# CONTROLSS_G3_EPWM29_CONTROLSS_G3_EPWM29 register map
Vendor: Texas Instruments
Registers are 16-bit, read-write, reset values left out (the file's numbers can be read two ways) unless marked. A register's access mark holds for its fields unless they carry their own. Offsets are as the file gives them; [hi:lo] are bit positions; {n}, {i} and the like mark numbered series.

## CONTROLSS_G3_EPWM29_CONTROLSS_G3_EPWM29 (part 3 of 4)
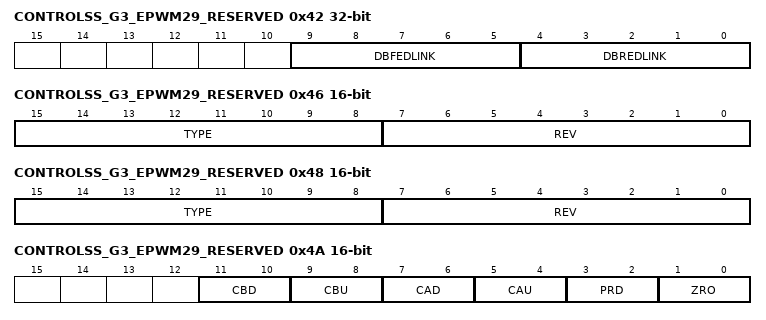
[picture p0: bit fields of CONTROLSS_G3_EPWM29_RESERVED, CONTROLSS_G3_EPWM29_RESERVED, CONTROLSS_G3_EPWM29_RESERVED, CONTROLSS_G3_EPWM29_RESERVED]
0x42 CONTROLSS_G3_EPWM29_RESERVED 32-bit
  [9:5] DBFEDLINK — DBFED_DBFEDHR Link Bits Writes to the DBFED:DBFEDHR registers in the ePWM module selected by the following bit selections results in a simultaneous write to the current ePWM module's DBFED_DBFEDHR registers. 00000: ePWM1 00001: ePWM2 00010: ePWM3 00011: ePWM4 00100: ePWM5 00101: ePWM6 00110: ePWM7 00111: ePWM8 01000: ePWM9 01001: ePWM10 01010: ePWM11 01011: ePWM12 01100: ePWM13 ... 11111: ePWM32
  [4:0] DBREDLINK — DBRED_DBREDHR Link Bits Writes to the DBRED:DBREDHR registers in the ePWM module selected by the following bit selections results in a simultaneous write to the current ePWM module's DBRED_DBREDHR registers. 00000: ePWM1 00001: ePWM2 00010: ePWM3 00011: ePWM4 00100: ePWM5 00101: ePWM6 00110: ePWM7 00111: ePWM8 01000: ePWM9 01001: ePWM10 01010: ePWM11 01011: ePWM12 01100: ePWM13 ... 11111: ePWM32
0x44 CONTROLSS_G3_EPWM29_RESERVED
  [0] CMPFIX_OVERRIDE — 0: Bug fix overriden 1: Bug fix takes effect
0x46 CONTROLSS_G3_EPWM29_RESERVED ro
  [15:8] TYPE — EPWM Type Bits: These bits specify the EPWM type. These bits are changed if the functionality of the EPWM is changed or any feature is added or removed:
  [7:0] REV — EPWM Silicon Revision Bits: These bits specify the EPWM revision. These bits are changed if any bug fixes are performed:
0x48 CONTROLSS_G3_EPWM29_RESERVED ro
  [15:8] TYPE — HRPWM Type Bits: These bits specify the HRPWM type. These bits are changed if the functionality of the HRPWM is changed or any feature is added or removed:
  [7:0] REV — HRPWM Silicon Revision Bits: These bits specify the HRPWM revision. These bits are changed if any bug fixes are performed:
0x4A CONTROLSS_G3_EPWM29_RESERVED
  [11:10] CBD — Action When TBCTR = CMPB on Down Count Note: By definition, in count up-down mode when the counter equals 0 the direction is defined as 1 or counting up. 00: Do nothing (action disabled) 01: Clear: force EPWMxA output low. 10: Set: force EPWMxA output high. 11: Toggle EPWMxA output: low output signal will be forced high, and a high signal will be forced low.
  [9:8] CBU — Action When TBCTR = CMPB on Up Count Note: By definition, in count up-down mode when the counter equals 0 the direction is defined as 1 or counting up. 00: Do nothing (action disabled) 01: Clear: force EPWMxA output low. 10: Set: force EPWMxA output high. 11: Toggle EPWMxA output: low output signal will be forced high, and a high signal will be forced low.
  [7:6] CAD — Action When TBCTR = CMPA on Down Count Note: By definition, in count up-down mode when the counter equals 0 the direction is defined as 1 or counting up. 00: Do nothing (action disabled) 01: Clear: force EPWMxA output low. 10: Set: force EPWMxA output high. 11: Toggle EPWMxA output: low output signal will be forced high, and a high signal will be forced low.
  [5:4] CAU — Action When TBCTR = CMPA on Up Count Note: By definition, in count up-down mode when the counter equals 0 the direction is defined as 1 or counting up. 00: Do nothing (action disabled) 01: Clear: force EPWMxA output low. 10: Set: force EPWMxA output high. 11: Toggle EPWMxA output: low output signal will be forced high, and a high signal will be forced low.
  [3:2] PRD — Action When TBCTR = TBPRD Note: By definition, in count up-down mode when the counter equals 0 the direction is defined as 1 or counting up. 00: Do nothing (action disabled) 01: Clear: force EPWMxA output low. 10: Set: force EPWMxA output high. 11: Toggle EPWMxA output: low output signal will be forced high, and a high signal will be forced low.
  [1:0] ZRO — Action When TBCTR = 0 Note: By definition, in count up-down mode when the counter equals 0 the direction is defined as 1 or counting up. 00: Do nothing (action disabled) 01: Clear: force EPWMxA output low. 10: Set: force EPWMxA output high. 11: Toggle EPWMxA output: low output signal will be forced high, and a high signal will be forced low.
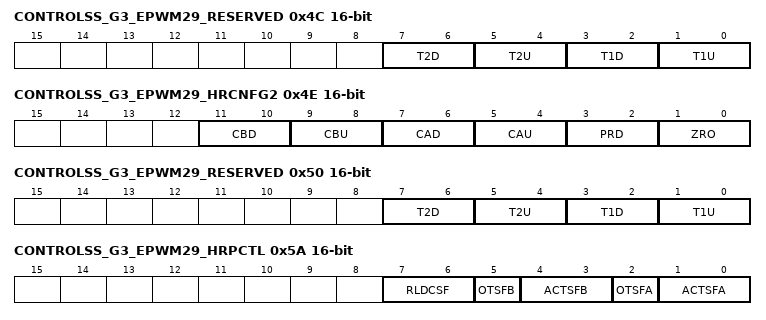
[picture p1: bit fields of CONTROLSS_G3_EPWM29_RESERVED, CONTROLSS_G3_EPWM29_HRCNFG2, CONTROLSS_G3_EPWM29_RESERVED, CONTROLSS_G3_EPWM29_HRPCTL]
0x4C CONTROLSS_G3_EPWM29_RESERVED
  [7:6] T2D — Action when event occurs on T2 in DOWN-Count Note: By definition, in count up-down mode when the counter equals 0 the direction is defined as 1 or counting up. 00: Do nothing (action disabled) 01: Clear: force EPWMxA output low. 10: Set: force EPWMxA output high. 11: Toggle EPWMxA output: low output signal will be forced high, and a high signal will be forced low.
  [5:4] T2U — Action when event occurs on T2 in UP-Count Note: By definition, in count up-down mode when the counter equals 0 the direction is defined as 1 or counting up. 00: Do nothing (action disabled) 01: Clear: force EPWMxA output low. 10: Set: force EPWMxA output high. 11: Toggle EPWMxA output: low output signal will be forced high, and a high signal will be forced low.
  [3:2] T1D — Action when event occurs on T1 in DOWN-Count Note: By definition, in count up-down mode when the counter equals 0 the direction is defined as 1 or counting up. 00: Do nothing (action disabled) 01: Clear: force EPWMxA output low. 10: Set: force EPWMxA output high. 11: Toggle EPWMxA output: low output signal will be forced high, and a high signal will be forced low.
  [1:0] T1U — Action when event occurs on T1 in UP-Count Note: By definition, in count up-down mode when the counter equals 0 the direction is defined as 1 or counting up. 00: Do nothing (action disabled) 01: Clear: force EPWMxA output low. 10: Set: force EPWMxA output high. 11: Toggle EPWMxA output: low output signal will be forced high, and a high signal will be forced low.
0x4E CONTROLSS_G3_EPWM29_HRCNFG2
  [11:10] CBD — Action When TBCTR = CMPB on Down Count Note: By definition, in count up-down mode when the counter equals 0 the direction is defined as 1 or counting up. 00: Do nothing (action disabled) 01: Clear: force EPWMxB output low. 10: Set: force EPWMxB output high. 11: Toggle EPWMxB output: low output signal will be forced high, and a high signal will be forced low.
  [9:8] CBU — Action When TBCTR = CMPB on Up Count Note: By definition, in count up-down mode when the counter equals 0 the direction is defined as 1 or counting up. 00: Do nothing (action disabled) 01: Clear: force EPWMxB output low. 10: Set: force EPWMxB output high. 11: Toggle EPWMxB output: low output signal will be forced high, and a high signal will be forced low.
  [7:6] CAD — Action When TBCTR = CMPA on Down Count Note: By definition, in count up-down mode when the counter equals 0 the direction is defined as 1 or counting up. 00: Do nothing (action disabled) 01: Clear: force EPWMxB output low. 10: Set: force EPWMxB output high. 11: Toggle EPWMxB output: low output signal will be forced high, and a high signal will be forced low.
  [5:4] CAU — Action When TBCTR = CMPA on Up Count Note: By definition, in count up-down mode when the counter equals 0 the direction is defined as 1 or counting up. 00: Do nothing (action disabled) 01: Clear: force EPWMxB output low. 10: Set: force EPWMxB output high. 11: Toggle EPWMxB output: low output signal will be forced high, and a high signal will be forced low.
  [3:2] PRD — Action When TBCTR = TBPRD Note: By definition, in count up-down mode when the counter equals 0 the direction is defined as 1 or counting up. 00: Do nothing (action disabled) 01: Clear: force EPWMxB output low. 10: Set: force EPWMxB output high. 11: Toggle EPWMxB output: low output signal will be forced high, and a high signal will be forced low.
  [1:0] ZRO — Action When TBCTR = 0 Note: By definition, in count up-down mode when the counter equals 0 the direction is defined as 1 or counting up. 00: Do nothing (action disabled) 01: Clear: force EPWMxB output low. 10: Set: force EPWMxB output high. 11: Toggle EPWMxB output: low output signal will be forced high, and a high signal will be forced low.
0x50 CONTROLSS_G3_EPWM29_RESERVED
  [7:6] T2D — Action when event occurs on T2 in DOWN-Count Note: By definition, in count up-down mode when the counter equals 0 the direction is defined as 1 or counting up. 00: Do nothing (action disabled) 01: Clear: force EPWMxB output low. 10: Set: force EPWMxB output high. 11: Toggle EPWMxB output: low output signal will be forced high, and a high signal will be forced low.
  [5:4] T2U — Action when event occurs on T2 in UP-Count Note: By definition, in count up-down mode when the counter equals 0 the direction is defined as 1 or counting up. 00: Do nothing (action disabled) 01: Clear: force EPWMxB output low. 10: Set: force EPWMxB output high. 11: Toggle EPWMxB output: low output signal will be forced high, and a high signal will be forced low.
  [3:2] T1D — Action when event occurs on T1 in DOWN-Count Note: By definition, in count up-down mode when the counter equals 0 the direction is defined as 1 or counting up. 00: Do nothing (action disabled) 01: Clear: force EPWMxB output low. 10: Set: force EPWMxB output high. 11: Toggle EPWMxB output: low output signal will be forced high, and a high signal will be forced low.
  [1:0] T1U — Action when event occurs on T1 in UP-Count Note: By definition, in count up-down mode when the counter equals 0 the direction is defined as 1 or counting up. 00: Do nothing (action disabled) 01: Clear: force EPWMxB output low. 10: Set: force EPWMxB output high. 11: Toggle EPWMxB output: low output signal will be forced high, and a high signal will be forced low.
0x5A CONTROLSS_G3_EPWM29_HRPCTL access not given
  [7:6] RLDCSF rw — AQCSFRC Active Register Reload From Shadow Options 00: Load on event counter equals zero 01: Load on event counter equals period 10: Load on event counter equals zero or counter equals period 11: Load immediately (the active register is directly accessed by the CPU and is not loaded from the shadow register).
  [5] OTSFB — One-Time Software Forced Event on Output B 0: Writing a 0 (zero) has no effect. Always reads back a 0. This bit is auto cleared once a write to this register is complete (i.e., a forced event is initiated.). This is a one-shot forced event. It can be overridden by another subsequent event on output B. 1: Initiates a single software forced event (access RW RRETURNS0S)
  [4:3] ACTSFB rw — Action When One-Time Software Force B is Invoked 00: Does nothing (action disabled) 01: Clear (low) 10: Set (high) 11: Toggle (Low -' High, High -' Low) Note: This action is not qualified by counter direction (CNT_dir)
  [2] OTSFA — One-Time Software Forced Event on Output A 0: Writing a 0 (zero) has no effect. Always reads back a 0. This bit is auto cleared once a write to this register is complete ( i.e., a forced event is initiated). This is a one-shot forced event. It can be overridden by another subsequent event on output A. 1: Initiates a single software forced event (access RW RRETURNS0S)
  [1:0] ACTSFA rw — Action When One-Time Software Force A Is Invoked 00: Does nothing (action disabled) 01: Clear (low) 10: Set (high) 11: Toggle (Low -' High, High -' Low) Note: This action is not qualified by counter direction (CNT_dir)
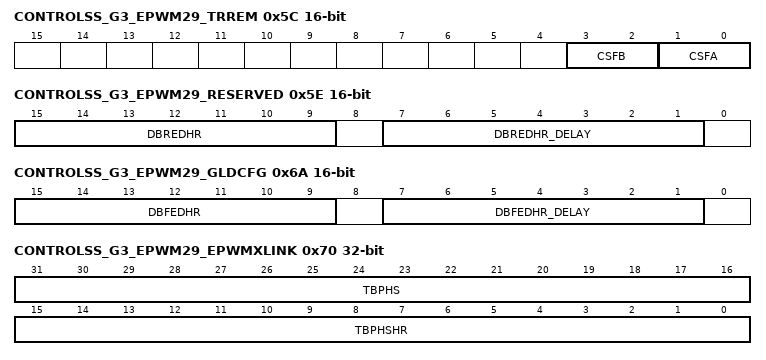
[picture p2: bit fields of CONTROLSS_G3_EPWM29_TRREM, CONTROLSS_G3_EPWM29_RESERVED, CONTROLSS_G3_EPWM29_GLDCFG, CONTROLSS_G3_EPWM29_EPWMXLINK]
0x5C CONTROLSS_G3_EPWM29_TRREM
  [3:2] CSFB — Continuous Software Force on Output B In immediate mode, a continuous force takes effect on the next TBCLK edge. In shadow mode, a continuous force takes effect on the next TBCLK edge after a shadow load into the active register. To configure shadow mode, use AQSFRC[RLDCSF]. 00: Software forcing is disabled and has no effect 01: Forces a continuous low on output B 10: Forces a continuous high on output B 11: Software forcing is disabled and has no effect
  [1:0] CSFA — Continuous Software Force on Output A In immediate mode, a continuous force takes effect on the next TBCLK edge. In shadow mode, a continuous force takes effect on the next TBCLK edge after a shadow load into the active register. 00: Software forcing is disabled and has no effect 01: Forces a continuous low on output A 10: Forces a continuous high on output A 11: Software forcing is disabled and has no effect
0x5E CONTROLSS_G3_EPWM29_RESERVED access per field
  [15:9] DBREDHR rw — Dead Band Rising Edge Delay High Resolution Bits
  [7:1] DBREDHR_DELAY ro — These 7-bits contain the results of OTTO calculation (if auto-conversion is enabled)
0x68 CONTROLSS_G3_EPWM29_GLDCTL
  [13:0] DBRED — Rising edge delay value
0x6A CONTROLSS_G3_EPWM29_GLDCFG access per field
  [15:9] DBFEDHR rw — Dead Band Falling Edge Delay High Resolution Bits
  [7:1] DBFEDHR_DELAY ro — These 7-bits contain the results of OTTO calculation (if auto-conversion is enabled)
0x6C CONTROLSS_G3_EPWM29_RESERVED
  [13:0] DBFED — Falling Edge Delay Count 14-bit counter
0x70 CONTROLSS_G3_EPWM29_EPWMXLINK 32-bit
  [31:16] TBPHS — Phase Offset Register These bits set time-base counter phase of the selected ePWM relative to the time-base that is supplying the synchronization input signal. - If TBCTL[PHSEN] = 0, then the synchronization event is ignored and the time-base counter is not loaded with the phase. - If TBCTL[PHSEN] = 1, then the time-base counter (TBCTR) will be loaded with the phase (TBPHS) when a synchronization event occurs. The synchronization event can be initiated by the input synchronization signal (EPWMxSYNCI) or by a software forced synchronization.
  [15:0] TBPHSHR — Phase Offset (High Resolution) Register. TBPHSHR must not be used. Instead TRREM (HRPWM remainder register) must be used to mimic the functionality of TBPHSHR. The lower 8 bits in this register are ignored - writes are ignored and reads return zero
0x74 CONTROLSS_G3_EPWM29_EPWMXLINK2
  [15:0] TBPRDHR — Period High Resolution Bits The upper 8-bits contain the high-resolution portion of the period value. The TBPRDHR register is not affected by the TBCTL[PRDLD] bit. Reads from this register always reflect the shadow register. Likewise writes are also to the shadow register. The TBPRDHR register is only used when the high resolution period feature is enabled. This register is only available with ePWM modules which support high-resolution period control. The lower 8 bits in this register are ignored - writes are ignored and reads return zero
0x78 CONTROLSS_G3_EPWM29_RESERVED
  [15:0] TBPRD — Time Base Period Register These bits determine the period of the time-base counter. This sets the PWM frequency. Shadowing of this register is enabled and disabled by the TBCTL[PRDLD] bit. By default this register is shadowed. - If TBCTL[PRDLD] = 0, then the shadow is enabled and any write or read will automatically go to the shadow register. In this case, the active register will be loaded from the shadow register when the time-base counter equals zero. - If TBCTL[PRDLD] = 1, then the shadow is disabled and any write or read will go directly to the active register, that is the register actively controlling the hardware. - The active and shadow registers share the same memory map address.
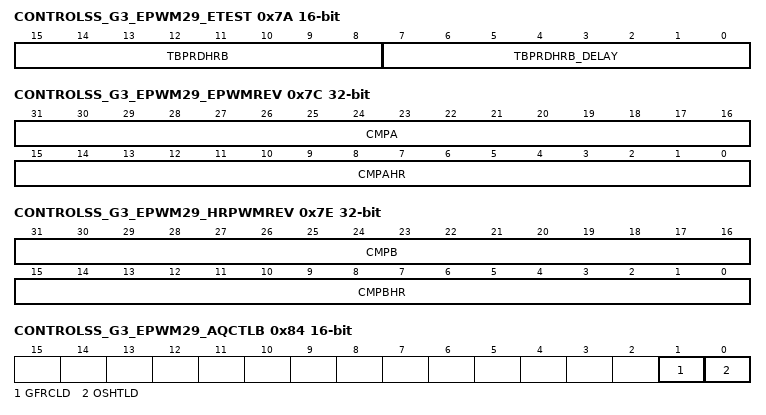
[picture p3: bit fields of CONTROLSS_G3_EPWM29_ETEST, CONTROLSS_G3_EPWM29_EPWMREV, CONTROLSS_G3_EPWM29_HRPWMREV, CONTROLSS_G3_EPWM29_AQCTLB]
0x7A CONTROLSS_G3_EPWM29_ETEST
  [15:8] TBPRDHRB — TBPRD High Resolution Calculation (2) Results for EPWMxB HRPWM Equations
  [7:0] TBPRDHRB_DELAY
0x7C CONTROLSS_G3_EPWM29_EPWMREV 32-bit
  [31:16] CMPA — Compare A Register The value in the active CMPA register is continuously compared to the time-base counter (TBCTR). When the values are equal, the counter-compare module generates a 'time-base counter equal to counter compare A' event. This event is sent to the action-qualifier where it is qualified and converted it into one or more actions. These actions can be applied to either the EPWMxA or the EPWMxB output depending on the configuration of the AQCTLA and AQCTLB registers. The actions that can be defined in the AQCTLA and AQCTLB registers include: - Do nothing the event is ignored. - Clear: Pull the EPWMxA and/or EPWMxB signal low - Set: Pull the EPWMxA and/or EPWMxB signal high - Toggle the EPWMxA and/or EPWMxB signal Shadowing of this register is enabled and disabled by the CMPCTL[SHDWAMODE] bit. By default this register is shadowed. - If CMPCTL[SHDWAMODE] = 0, then the shadow is enabled and anywrite or read will automatically go to the shadow register. In this case, the CMPCTL[LOADAMODE] bit field determines which event will load the active register from the shadow register. - Before a write, the CMPCTL[SHDWAFULL] bit can be read to determine if the shadow register is currently full. - If CMPCTL[SHDWAMODE] = 1, then the shadow register is disabled and any write or read will go directly to the active register, that is the register actively controlling the hardware. - In either mode, the active and shadow registers share the same memory map address.
  [15:0] CMPAHR — Compare A HRPWM Extension Register The UPPER 8-bits contain the high-resolution portion (most significant 8-bits) of the counter-compare A value. CMPA:CMPAHR can be accessed in a single 32-bit read/write. Shadowing is enabled and disabled by the CMPCTL[SHDWAMODE] bit as described for the CMPA register. The lower 8 bits in this register are ignored
0x7E CONTROLSS_G3_EPWM29_HRPWMREV 32-bit
  [31:16] CMPB — Compare B Register The value in the active CMPB register is continuously compared to the time-base counter (TBCTR). When the values are equal, the counter-compare module generates a 'time-base counter equal to counter compare B' event. This event is sent to the action-qualifier where it is qualified and converted it into one or more actions. These actions can be applied to either the EPWMxA or the EPWMxB output depending on the configuration of the AQCTLA and AQCTLB registers. The actions that can be defined in the AQCTLA and AQCTLB registers include: - Do nothing the event is ignored. - Clear: Pull the EPWMxA and/or EPWMxB signal low - Set: Pull the EPWMxA and/or EPWMxB signal high - Toggle the EPWMxA and/or EPWMxB signal Shadowing of this register is enabled and disabled by the CMPCTL[SHDWBMODE] bit. By default this register is shadowed. - If CMPCTL[SHDWBMODE] = 0, then the shadow is enabled and anywrite or read will automatically go to the shadow register. In this case, the CMPCTL[LOADBMODE] bit field determines which event will load the active register from the shadow register. - Before a write, the CMPCTL[SHDWBFULL] bit can be read to determine if the shadow register is currently full. - If CMPCTL[SHDWBMODE] = 1, then the shadow register is disabled and any write or read will go directly to the active register, that is the register actively controlling the hardware. - In either mode, the active and shadow registers share the same memory map address.
  [15:0] CMPBHR — Compare B High Resolution Bits The lower 8 bits in this register are ignored
0x80 CONTROLSS_G3_EPWM29_AQCTLA
  [15:0] CMPC — Compare C Register The value in the active CMPC register is continuously compared to the time-base counter (TBCTR). When the values are equal, the counter-compare module generates a 'time-base counter equal to counter compare C' event. Shadowing of this register is enabled and disabled by the CMPCTL2[SHDWCMODE] bit. By default this register is shadowed. - If CMPCTL2[SHDWCMODE] = 0, then the shadow is enabled and any write or read will automatically go to the shadow register. In this case, the CMPCTL2[LOADCMODE] bit field determines which event will load the active register from the shadow register: - If CMPCTL2[SHDWCMODE] = 1, then the shadow register is disabled and any write or read will go directly to the active register that is, the register actively controlling the hardware. - In either mode, the active and shadow registers share the same memory map address.
0x82 CONTROLSS_G3_EPWM29_AQCTLA2
  [15:0] CMPD — Compare D Register The value in the active CMPD register is continuously compared to the time-base counter (TBCTR). When the values are equal, the counter-compare module generates a 'time-base counter equal to counter compare D' event. Shadowing of this register is enabled and disabled by the CMPCTL2[SHDWDMODE] bit. By default this register is shadowed. - If CMPCTL2[SHDWDMODE] = 0, then the shadow is enabled and any write or read will automatically go to the shadow register. In this case, the CMPCTL2[LOADDMODE] bit field determines which event will load the active register from the shadow register: - If CMPCTL2[SHDWDMODE] = 1, then the shadow register is disabled and any write or read will go directly to the active register that is, the register actively controlling the hardware. - In either mode, the active and shadow registers share the same memory map address.
0x84 CONTROLSS_G3_EPWM29_AQCTLB access not given
  [1] GFRCLD — Force Load Event in One Shot Mode 0: Writing of 0 will be ignored. Always reads back a 0. 1: Force one load event at the input of the event pre-scale counter as shown in the diagram below. This bit is intended to be used for testing and/or software force loading of the events in global load mode. (access RW RRETURNS0S)
  [0] OSHTLD — Enable Reload Event in One Shot Mode 0: Writing of 0 will be ignored. Always reads back a 0. 1: Turns the one shot latch condition ON. Upon occurrence of a chosen load strobe, one shadow to active reload occurs and the latch will be cleared. Hence writing 1 to this bit would allow one load strobe event to pass through and block further strobe events. (access RW RRETURNS0S)
0x86 CONTROLSS_G3_EPWM29_AQCTLB2
  [15:0] SWVDELVAL — Software Valley Delay Value Register This register can be optionally used define offset value for the hardware calculated delay HWDELAYVAL as defined in VCAPCTL[VDELAYDIV] bits.
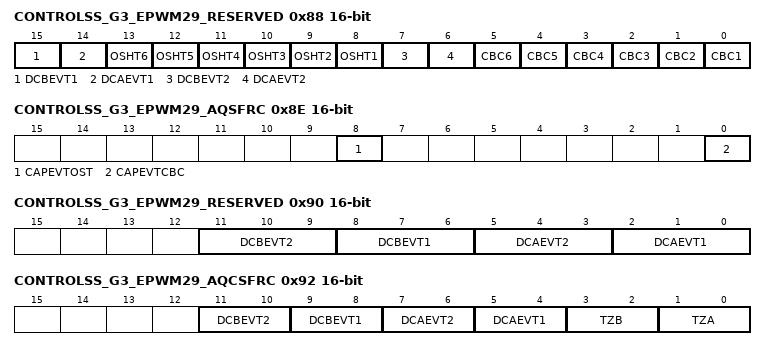
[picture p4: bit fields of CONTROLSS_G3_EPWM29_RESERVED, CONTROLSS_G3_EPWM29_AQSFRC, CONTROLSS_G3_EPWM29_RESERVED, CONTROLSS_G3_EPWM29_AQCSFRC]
0x88 CONTROLSS_G3_EPWM29_RESERVED
  [15] DCBEVT1 — Digital Compare Output B Event 1 Select 0: Disable DCBEVT1 as one-shot-trip source for this ePWM module. 1: Enable DCBEVT1 as one-shot-trip source for this ePWM module.
  [14] DCAEVT1 — Digital Compare Output A Event 1 Select 0: Disable DCAEVT1 as one-shot-trip source for this ePWM module. 1: Enable DCAEVT1 as one-shot-trip source for this ePWM module.
  [n+7] OSHT{n} (n=1..6) — Trip-zone {n} (TZ{n}) Select 0: Disable TZ{n} as a one-shot trip source for this ePWM module 1: Enable TZ{n} as a one-shot trip source for this ePWM module
  [7] DCBEVT2 — Digital Compare Output B Event 2 Select 0: Disable DCBEVT2 as a CBC trip source for this ePWM module 1: Enable DCBEVT2 as a CBC trip source for this ePWM module
  [6] DCAEVT2 — Digital Compare Output A Event 2 Select 0: Disable DCAEVT2 as a CBC trip source for this ePWM module 1: Enable DCAEVT2 as a CBC trip source for this ePWM module
  [n-1] CBC{n} (n=1..6) — Trip-zone {n} (TZ{n}) Select 0: Disable TZ{n} as a CBC trip source for this ePWM module 1: Enable TZ{n} as a CBC trip source for this ePWM module
0x8E CONTROLSS_G3_EPWM29_AQSFRC
  [8] CAPEVTOST — CAPEVT OST Select 0: Disable CAPEVT as a one-shot trip source for this ePWM module 1: Enable CAPEVT as a one-shot trip source for this ePWM module
  [0] CAPEVTCBC — CAPEVT CBC mode Select 0: Disable CAPEVT as a CBC trip source for this ePWM module 1: Enable CAPEVT as a CBC trip source for this ePWM module
0x90 CONTROLSS_G3_EPWM29_RESERVED
  [11:9] DCBEVT2 — Digital Compare Output B Event 2 Selection 000: Event disabled 001: DCBH = low, DCBL = don't care 010: DCBH = high, DCBL = don't care 011: DCBL = low, DCBH = don't care 100: DCBL = high, DCBH = don't care 101: DCBL = high, DCBH = low 110: Reserved 111: Reserved
  [8:6] DCBEVT1 — Digital Compare Output B Event 1 Selection 000: Event disabled 001: DCBH = low, DCBL = don't care 010: DCBH = high, DCBL = don't care 011: DCBL = low, DCBH = don't care 100: DCBL = high, DCBH = don't care 101: DCBL = high, DCBH = low 110: Reserved 111: Reserved
  [5:3] DCAEVT2 — Digital Compare Output A Event 2 Selection 000: Event disabled 001: DCAH = low, DCAL = don't care 010: DCAH = high, DCAL = don't care 011: DCAL = low, DCAH = don't care 100: DCAL = high, DCAH = don't care 101: DCAL = high, DCAH = low 110: Reserved 111: Reserved
  [2:0] DCAEVT1 — Digital Compare Output A Event 1 Selection 000: Event disabled 001: DCAH = low, DCAL = don't care 010: DCAH = high, DCAL = don't care 011: DCAL = low, DCAH = don't care 100: DCAL = high, DCAH = don't care 101: DCAL = high, DCAH = low 110: Reserved 111: Reserved
0x92 CONTROLSS_G3_EPWM29_AQCSFRC
  [11:10] DCBEVT2 — Digital Compare Output B Event 2 Action On EPWMxB 00: High-impedance (EPWMxB = High-impedance state) 01: Force EPWMxB to a high state. 10: Force EPWMxB to a low state. 11: Do Nothing, trip action is disabled
  [9:8] DCBEVT1 — Digital Compare Output B Event 1 Action On EPWMxB 00: High-impedance (EPWMxB = High-impedance state) 01: Force EPWMxB to a high state. 10: Force EPWMxB to a low state. 11: Do Nothing, trip action is disabled
  [7:6] DCAEVT2 — Digital Compare Output A Event 2 Action On EPWMxA 00: High-impedance (EPWMxA = High-impedance state) 01: Force EPWMxA to a high state. 10: Force EPWMxA to a low state. 11: Do Nothing, trip action is disabled
  [5:4] DCAEVT1 — Digital Compare Output A Event 1 Action On EPWMxA 00: High-impedance (EPWMxA = High-impedance state) 01: Force EPWMxA to a high state. 10: Force EPWMxA to a low state. 11: Do Nothing, trip action is disabled
  [3:2] TZB — TZ1 to TZ6, DCAEVT1/2, DCBEVT1/2Trip Action On EPWMxB When a trip event occurs the following action is taken on output EPWMxB. Which trip-zone pins can cause an event is defined in the TZSEL register. 00: High-impedance (EPWMxB = High-impedance state) 01: Force EPWMxB to a high state 10: Force EPWMxB to a low state 11: Do nothing, no action is taken on EPWMxB.
  [1:0] TZA — TZ1 to TZ6, DCAEVT1/2, DCBEVT1/2 Trip Action On EPWMxA When a trip event occurs the following action is taken on output EPWMxA. Which trip-zone pins can cause an event is defined in the TZSEL register. 00: High-impedance (EPWMxA = High-impedance state) 01: Force EPWMxA to a high state 10: Force EPWMxA to a low state 11: Do nothing, no action is taken on EPWMxA.
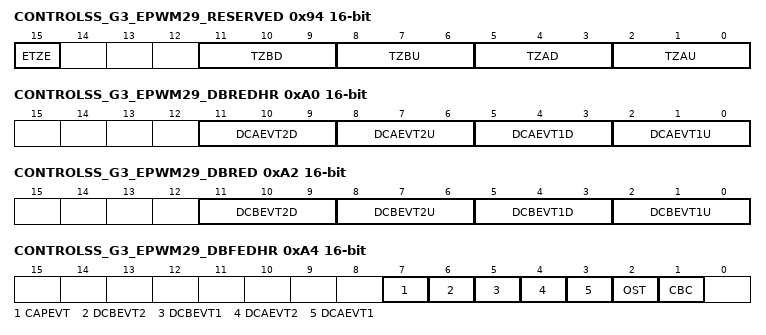
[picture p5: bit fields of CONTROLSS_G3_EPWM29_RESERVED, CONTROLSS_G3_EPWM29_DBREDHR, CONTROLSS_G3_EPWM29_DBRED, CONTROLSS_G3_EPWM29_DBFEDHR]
0x94 CONTROLSS_G3_EPWM29_RESERVED
  [15] ETZE — TZCTL2 Enable 0: Use trip action from TZCTL (legacy EPWM compatibility) 1: Use trip action defined in TZCTL2, TZCTLDCA and TZCTLDCB. Settings in TZCTL are ignored
  [11:9] TZBD — TZ1 to TZ6 Trip Action On EPWMxB while Count direction is DOWN 000: HiZ (EPWMxB = HiZ state) 001: Forced Hi (EPWMxB = High state) 010: Forced Lo (EPWMxB = Lo state) 011: Toggle (Low -' High, High -' Low) 100: Reserved 101: Reserved 110: Reserved 111: Do Nothing, trip action is disabled
  [8:6] TZBU — TZ1 to TZ6, DCAEVT1/2, DCBEVT1/2 Trip Action On EPWMxB while Count direction is UP 000: HiZ (EPWMxB = HiZ state) 001: Forced Hi (EPWMxB = High state) 010: Forced Lo (EPWMxB = Lo state) 011: Toggle (Low -' High, High -' Low) 100: Reserved 101: Reserved 110: Reserved 111: Do Nothing, trip action is disabled
  [5:3] TZAD — TZ1 to TZ6, DCAEVT1/2, DCBEVT1/2 Trip Action On EPWMxA while Count direction is DOWN 000: HiZ (EPWMxA = HiZ state) 001: Forced Hi (EPWMxA = High state) 010: Forced Lo (EPWMxA = Lo state) 011: Toggle (Low -' High, High -' Low) 100: Reserved 101: Reserved 110: Reserved 111: Do Nothing, trip action is disabled
  [2:0] TZAU — TZ1 to TZ6, DCAEVT1/2, DCBEVT1/2 Trip Action On EPWMxA while Count direction is UP 000: HiZ (EPWMxA = HiZ state) 001: Forced Hi (EPWMxA = High state) 010: Forced Lo (EPWMxA = Lo state) 011: Toggle (Low -' High, High -' Low) 100: Reserved 101: Reserved 110: Reserved 111: Do Nothing, trip action is disabled
0xA0 CONTROLSS_G3_EPWM29_DBREDHR
  [11:9] DCAEVT2D — Digital Compare Output A Event 2 Action On EPWMxA while Count direction is DOWN 000: HiZ (EPWMxA = HiZ state) 001: Forced Hi (EPWMxA = High state) 010: Forced Lo (EPWMxA = Lo state) 011: Toggle (Low -' High, High -' Low) 100: Reserved 101: Reserved 110: Reserved 111: Do Nothing, trip action is disabled
  [8:6] DCAEVT2U — Digital Compare Output A Event 2 Action On EPWMxA while Count direction is UP 000: HiZ (EPWMxA = HiZ state) 001: Forced Hi (EPWMxA = High state) 010: Forced Lo (EPWMxA = Lo state) 011: Toggle (Low -' High, High -' Low) 100: Reserved 101: Reserved 110: Reserved 111: Do Nothing, trip action is disabled
  [5:3] DCAEVT1D — Digital Compare Output A Event 1 Action On EPWMxA while Count direction is DOWN 000: HiZ (EPWMxA = HiZ state) 001: Forced Hi (EPWMxA = High state) 010: Forced Lo (EPWMxA = Lo state) 011: Toggle (Low -' High, High -' Low) 100: Reserved 101: Reserved 110: Reserved 111: Do Nothing, trip action is disabled
  [2:0] DCAEVT1U — Digital Compare Output A Event 1 Action On EPWMxA while Count direction is UP 000: HiZ (EPWMxA = HiZ state) 001: Forced Hi (EPWMxA = High state) 010: Forced Lo (EPWMxA = Lo state) 011: Toggle (Low -' High, High -' Low) 100: Reserved 101: Reserved 110: Reserved 111: Do Nothing, trip action is disabled
0xA2 CONTROLSS_G3_EPWM29_DBRED
  [11:9] DCBEVT2D — Digital Compare Output B Event 2 Action On EPWMxB while Count direction is DOWN 000: HiZ (EPWMxB = HiZ state) 001: Forced Hi (EPWMxB = High state) 010: Forced Lo (EPWMxB = Lo state) 011: Toggle (Low -' High, High -' Low) 100: Reserved 101: Reserved 110: Reserved 111: Do Nothing, trip action is disabled
  [8:6] DCBEVT2U — Digital Compare Output B Event 2 Action On EPWMxB while Count direction is UP 000: HiZ (EPWMxB = HiZ state) 001: Forced Hi (EPWMxB = High state) 010: Forced Lo (EPWMxB = Lo state) 011: Toggle (Low -' High, High -' Low) 100: Reserved 101: Reserved 110: Reserved 111: Do Nothing, trip action is disabled
  [5:3] DCBEVT1D — Digital Compare Output B Event 1 Action On EPWMxB while Count direction is DOWN 000: HiZ (EPWMxB = HiZ state) 001: Forced Hi (EPWMxB = High state) 010: Forced Lo (EPWMxB = Lo state) 011: Toggle (Low -' High, High -' Low) 100: Reserved 101: Reserved 110: Reserved 111: Do Nothing, trip action is disabled
  [2:0] DCBEVT1U — Digital Compare Output B Event 1 Action On EPWMxB while Count direction is UP 000: HiZ (EPWMxB = HiZ state) 001: Forced Hi (EPWMxB = High state) 010: Forced Lo (EPWMxB = Lo state) 011: Toggle (Low -' High, High -' Low) 100: Reserved 101: Reserved 110: Reserved 111: Do Nothing, trip action is disabled
0xA4 CONTROLSS_G3_EPWM29_DBFEDHR
  [7] CAPEVT — Capture Event Interrupt Enable 0: Disabled 1: Enabled
  [6] DCBEVT2 — Digital Compare Output B Event 2 Interrupt Enable 0: Disabled 1: Enabled
  [5] DCBEVT1 — Digital Compare Output B Event 1 Interrupt Enable 0: Disabled 1: Enabled
  [4] DCAEVT2 — Digital Compare Output A Event 2 Interrupt Enable 0: Disabled 1: Enabled
  [3] DCAEVT1 — Digital Compare Output A Event 1 Interrupt Enable 0: Disabled 1: Enabled
  [2] OST — Trip-zone One-Shot Interrupt Enable 0: Disable one-shot interrupt generation 1: Enable Interrupt generation a one-shot trip event will cause a EPWMx_TZINT PIE interrupt.
  [1] CBC — Trip-zone Cycle-by-Cycle Interrupt Enable 0: Disable cycle-by-cycle interrupt generation. 1: Enable interrupt generation a cycle-by-cycle trip event will cause an EPWMx_TZINT PIE interrupt.
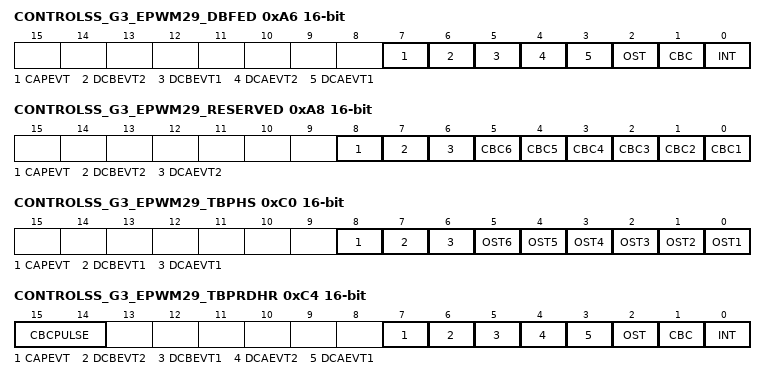
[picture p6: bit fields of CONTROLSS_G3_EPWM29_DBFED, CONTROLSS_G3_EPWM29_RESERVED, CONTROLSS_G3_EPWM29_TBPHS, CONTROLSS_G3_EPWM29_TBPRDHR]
0xA6 CONTROLSS_G3_EPWM29_DBFED ro
  [7] CAPEVT — Latched Status Flag for Capture Event 0: Indicates no trip event has occurred on CAPEVT 1: Indicates a trip event has occurred for the event defined for CAPEVT
  [6] DCBEVT2 — Latched Status Flag for Digital Compare Output B Event 2 0: Indicates no trip event has occurred on DCBEVT2 1: Indicates a trip event has occurred for the event defined for DCBEVT2
  [5] DCBEVT1 — Latched Status Flag for Digital Compare Output B Event 1 0: Indicates no trip event has occurred on DCBEVT1 1: Indicates a trip event has occurred for the event defined for DCBEVT1
  [4] DCAEVT2 — Latched Status Flag for Digital Compare Output A Event 2 0: Indicates no trip event has occurred on DCAEVT2 1: Indicates a trip event has occurred for the event defined for DCAEVT2
  [3] DCAEVT1 — Latched Status Flag for Digital Compare Output A Event 1 0: Indicates no trip event has occurred on DCAEVT1 1: Indicates a trip event has occurred for the event defined for DCAEVT1
  [2] OST — Latched Status Flag for A One-Shot Trip Event 0: No one-shot trip event has occurred. 1: Indicates a trip event has occurred on a pin selected as a one-shot trip source. This bit is cleared by writing the appropriate value to the TZCLR register.
  [1] CBC — Latched Status Flag for Cycle-By-Cycle Trip Event 0: No cycle-by-cycle trip event has occurred. 1: Indicates a trip event has occurred on a signal selected as a cycle-by-cycle trip source. The TZFLG[CBC] bit will remain set until it is manually cleared by the user. If the cycle-by-cycle trip event is still present when the CBC bit is cleared, then CBC will be immediately set again. The specified condition on the signal is automatically cleared when the ePWM time-base counter reaches zero (TBCTR = 0x00) if the trip condition is no longer present. The condition on the signal is only cleared when the TBCTR = 0x00 no matter where in the cycle the CBC flag is cleared. This bit is cleared by writing the appropriate value to the TZCLR register.
  [0] INT — Latched Trip Interrupt Status Flag 0: Indicates no interrupt has been generated. 1: Indicates an EPWMx_TZINT PIE interrupt was generated because of a trip condition. No further EPWMx_TZINT PIE interrupts will be generated until this flag is cleared. If the interrupt flag is cleared when either CBC or OST is set, then another interrupt pulse will be generated. Clearing all flag bits will prevent further interrupts. This bit is cleared by writing the appropriate value to the TZCLR register.
0xA8 CONTROLSS_G3_EPWM29_RESERVED ro
  [8] CAPEVT — Latched Status Flag for Capture Event 0: Indicates no trip event has occurred on CAPEVT 1: Indicates a trip event has occurred for the event defined for CAPEVT
  [7] DCBEVT2 — Latched Status Flag for Digital Compare B Output Event 2 Trip Latch 0: Reading a 0 indicates that no trip has occurred on DCBEVT2. 1: Reading a 1 indicates a trip has occured on the DCBEVT2 selected event.
  [6] DCAEVT2 — Latched Status Flag for Digital Compare A Output Event 2 Trip Latch 0: Reading a 0 indicates that no trip has occurred on DCAEVT2. 1: Reading a 1 indicates a trip has occured on the DCAEVT2 selected event.
  [n-1] CBC{n} (n=1..6) — Latched Status Flag for CBC{n} Trip Latch 0: Reading a 0 indicates that no trip has occurred on CBC{n}. 1: Reading a 1 indicates a trip has occured on the CBC{n} selected event.
0xC0 CONTROLSS_G3_EPWM29_TBPHS ro
  [8] CAPEVT — Latched Status Flag for Capture Event 0: Indicates no trip event has occurred on CAPEVT 1: Indicates a trip event has occurred for the event defined for CAPEVT
  [7] DCBEVT1 — Latched Status Flag for Digital Compare B Output Event 1 Trip Latch 0: Reading a 0 indicates that no trip has occurred on DCBEVT1. 1: Reading a 1 indicates a trip has occured on the DCBEVT1 selected event.
  [6] DCAEVT1 — Latched Status Flag for Digital Compare A Output Event 1 Trip Latch 0: Reading a 0 indicates that no trip has occurred on DCAEVT1. 1: Reading a 1 indicates a trip has occured on the DCAEVT1 selected event.
  [n-1] OST{n} (n=1..6) — Latched Status Flag for OST{n} Trip Latch 0: Reading a 0 indicates that no trip has occurred on OST{n}. 1: Reading a 1 indicates a trip has occured on the OST{n} selected event.
0xC4 CONTROLSS_G3_EPWM29_TBPRDHR access not given
  [15:14] CBCPULSE rw — Clear Pulse for Cycle-By-Cycle (CBC) Trip Latch This bit field determines which pulse clears the CBC trip latch. 00: CTR = zero pulse clears CBC trip latch. (Same as legacy designs.) 01: CTR = PRD pulse clears CBC trip latch. 10: CTR = zero or CTR = PRD pulse clears CBC trip latch. 11: CBC trip latch is not cleared
  [7] CAPEVT — Clear Flag for Capture Event 0: Writing 0 has no effect. This bit always reads back 0. 1: Writing 1 clears the CAPEVT event trip condition. (access RW RRETURNS0S)
  [6] DCBEVT2 — Clear Flag for Digital Compare Output B Event 2 0: Writing 0 has no effect. This bit always reads back 0. 1: Writing 1 clears the DCBEVT2 event trip condition. (access RW RRETURNS0S)
  [5] DCBEVT1 — Clear Flag for Digital Compare Output B Event 1 0: Writing 0 has no effect. This bit always reads back 0. 1: Writing 1 clears the DCBEVT1 event trip condition. (access RW RRETURNS0S)
  [4] DCAEVT2 — Clear Flag for Digital Compare Output A Event 2 0: Writing 0 has no effect. This bit always reads back 0. 1: Writing 1 clears the DCAEVT2 event trip condition. (access RW RRETURNS0S)
  [3] DCAEVT1 — Clear Flag for Digital Compare Output A Event 1 0: Writing 0 has no effect. This bit always reads back 0. 1: Writing 1 clears the DCAEVT1 event trip condition. (access RW RRETURNS0S)
  [2] OST — Clear Flag for One-Shot Trip (OST) Latch 0: Has no effect. Always reads back a 0. 1: Clears this Trip (set) condition. (access RW RRETURNS0S)
  [1] CBC — Clear Flag for Cycle-By-Cycle (CBC) Trip Latch 0: Has no effect. Always reads back a 0. 1: Clears this Trip (set) condition. (access RW RRETURNS0S)
  [0] INT — Global Interrupt Clear Flag 0: Has no effect. Always reads back a 0. 1: Clears the trip-interrupt flag for this ePWM module (TZFLG[INT]). NOTE: No further EPWMx_TZINT PIE interrupts will be generated until the flag is cleared. If the TZFLG[INT] bit is cleared and any of the other flag bits are set, then another interrupt pulse will be generated. Clearing all flag bits will prevent further interrupts. (access RW RRETURNS0S)
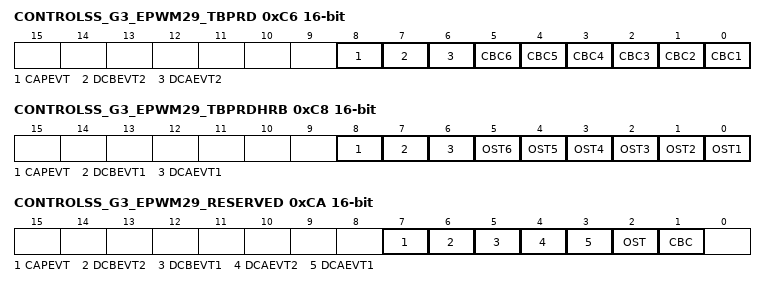
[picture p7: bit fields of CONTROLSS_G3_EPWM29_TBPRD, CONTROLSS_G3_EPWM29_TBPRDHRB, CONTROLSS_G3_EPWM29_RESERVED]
0xC6 CONTROLSS_G3_EPWM29_TBPRD access not given
  [8] CAPEVT — Clear Flag for CAPEVT selected for CBC 0: Writing a 0 has no effect. 1: Writing a 1 will clear the TZCBCFLG[CAPEVT] bit. (access RW RRETURNS0S)
  [7] DCBEVT2 — Clear Flag for Digital Compare Output B Event 2 selected for CBC 0: Writing a 0 has no effect. 1: Writing a 1 will clear the TZCBCFLG[DCBEVT2] bit. (access RW RRETURNS0S)
  [6] DCAEVT2 — Clear Flag for Digital Compare Output A Event 2 selected for CBC 0: Writing a 0 has no effect. 1: Writing a 1 will clear the TZCBCFLG[DCAEVT2] bit. (access RW RRETURNS0S)
  [n-1] CBC{n} (n=1..6) — Clear Flag for Cycle-By-Cycle (CBC{n}) Trip Latch 0: Writing a 0 has no effect. 1: Writing a 1 will clear the TZCBCFLG[CBC{n}] bit. (access RW RRETURNS0S)
0xC8 CONTROLSS_G3_EPWM29_TBPRDHRB access not given
  [8] CAPEVT — Clear Flag for CAPEVT selected for OST 0: Writing a 0 has no effect. 1: Writing a 1 will clear the TZOSTFLG[CAPEVT] bit. (access RW RRETURNS0S)
  [7] DCBEVT1 — Clear Flag for Digital Compare Output B Event 1 selected for OST 0: Writing a 0 has no effect. 1: Writing a 1 will clear the TZOSTFLG[DCBEVT1] bit. (access RW RRETURNS0S)
  [6] DCAEVT1 — Clear Flag for Digital Compare Output A Event 1 selected for OST 0: Writing a 0 has no effect. 1: Writing a 1 will clear the TZOSTFLG[DCAEVT1] bit. (access RW RRETURNS0S)
  [n-1] OST{n} (n=1..6) — Clear Flag for Oneshot (OST{n}) Trip Latch 0: Writing a 0 has no effect. 1: Writing a 1 will clear the TZOSTFLG[OST{n}] bit. (access RW RRETURNS0S)
0xCA CONTROLSS_G3_EPWM29_RESERVED access not given
  [7] CAPEVT — Force Flag for Capture Event Output 0: Writing 0 has no effect. This bit always reads back 0. 1: Writing 1 forces the CAPEVT event trip condition and sets the TZFLG[CAPEVT] bit. (access RW RRETURNS0S)
  [6] DCBEVT2 — Force Flag for Digital Compare Output B Event 2 0: Writing 0 has no effect. This bit always reads back 0. 1: Writing 1 forces the DCBEVT2 event trip condition and sets the TZFLG[DCBEVT2] bit. (access RW RRETURNS0S)
  [5] DCBEVT1 — Force Flag for Digital Compare Output B Event 1 0: Writing 0 has no effect. This bit always reads back 0. 1: Writing 1 forces the DCBEVT1 event trip condition and sets the TZFLG[DCBEVT1] bit. (access RW RRETURNS0S)
  [4] DCAEVT2 — Force Flag for Digital Compare Output A Event 2 0: Writing 0 has no effect. This bit always reads back 0. 1: Writing 1 forces the DCAEVT2 event trip condition and sets the TZFLG[DCAEVT2] bit. (access RW RRETURNS0S)
  [3] DCAEVT1 — Force Flag for Digital Compare Output A Event 1 0: Writing 0 has no effect. This bit always reads back 0 1: Writing 1 forces the DCAEVT1 event trip condition and sets the TZFLG[DCAEVT1] bit. (access RW RRETURNS0S)
  [2] OST — Force a One-Shot Trip Event via Software 0: Writing of 0 is ignored. Always reads back a 0. 1: Forces a one-shot trip event and sets the TZFLG[OST] bit. (access RW RRETURNS0S)
  [1] CBC — Force a Cycle-by-Cycle Trip Event via Software 0: Writing of 0 is ignored. Always reads back a 0. 1: Forces a cycle-by-cycle trip event and sets the TZFLG[CBC] bit. (access RW RRETURNS0S)
